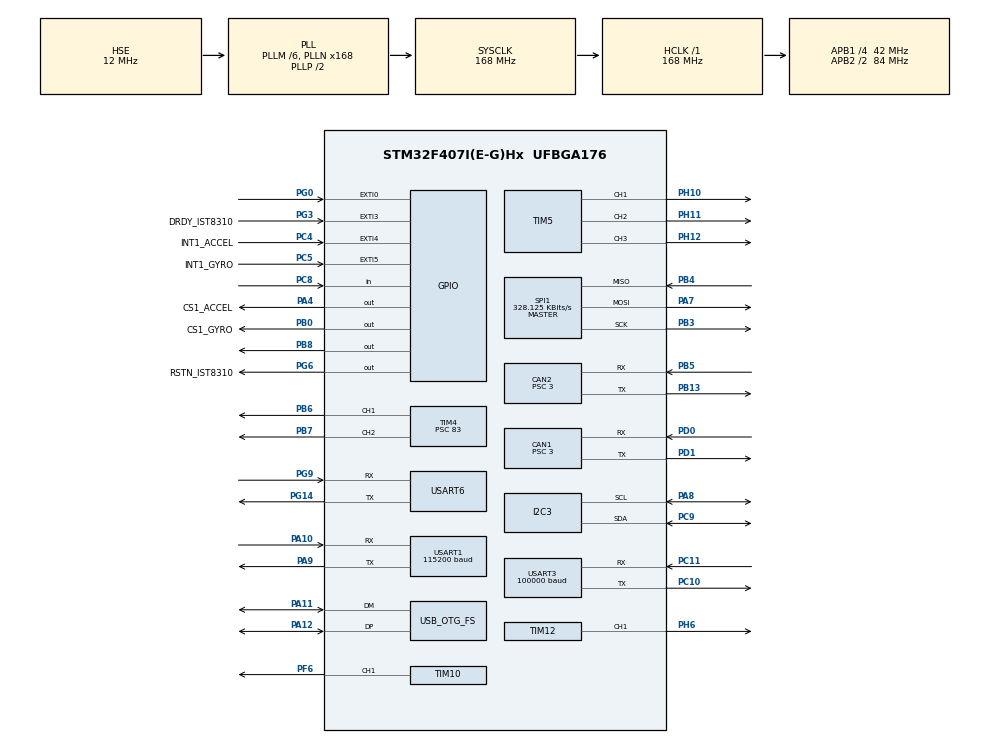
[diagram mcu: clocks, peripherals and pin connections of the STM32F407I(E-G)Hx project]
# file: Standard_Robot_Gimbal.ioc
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Dma.USART6_TX.3.MemInc=DMA_MINC_ENABLE
PH0-OSC_IN.Signal=RCC_OSC_IN
Dma.USART3_RX.1.Mode=DMA_NORMAL
Dma.USART6_TX.3.PeriphInc=DMA_PINC_DISABLE
PG6.PinState=GPIO_PIN_SET
PH12.Signal=S_TIM5_CH3
SPI1.VirtualType=VM_MASTER
PG6.GPIO_Label=RSTN_IST8310
PG0.Signal=GPXTI0
VP_RTC_VS_RTC_Activate.Mode=RTC_Enabled
Dma.SPI1_RX.4.PeriphInc=DMA_PINC_DISABLE
PB13.Signal=CAN2_TX
RCC.SYSCLKSource=RCC_SYSCLKSOURCE_PLLCLK
Dma.SPI1_TX.5.Instance=DMA2_Stream3
RTC.SynchPrediv=3199
USART3.BaudRate=100000
Dma.USART1_TX.0.Direction=DMA_MEMORY_TO_PERIPH
Dma.USART3_RX.1.Instance=DMA1_Stream1
NVIC.CAN1_TX_IRQn=true\:5\:0\:false\:false\:true\:true\:true\:true
SPI1.Direction=SPI_DIRECTION_2LINES
RCC.APB2TimFreq_Value=168000000
VP_TIM10_VS_ClockSourceINT.Mode=Enable_Timer
PB6.Signal=S_TIM4_CH1
SPI1.CalculateBaudRate=328.125 KBits/s
PD0.Signal=CAN1_RX
Dma.SPI1_RX.4.MemDataAlignment=DMA_MDATAALIGN_BYTE
PB3.Mode=Full_Duplex_Master
TIM10.Channel=TIM_CHANNEL_1
TIM12.Period=31111
PG14.Mode=Asynchronous
PG6.GPIO_PuPd=GPIO_PULLUP
SH.S_TIM12_CH1.0=TIM12_CH1,PWM Generation1 CH1
PC4.GPIO_Label=INT1_ACCEL
Dma.USART3_RX.1.Priority=DMA_PRIORITY_HIGH
PC9.Mode=I2C
SH.S_TIM4_CH2.0=TIM4_CH2,PWM Generation2 CH2
Dma.SPI1_TX.5.FIFOMode=DMA_FIFOMODE_DISABLE
PA8.Signal=I2C3_SCL
Dma.SPI1_TX.5.Priority=DMA_PRIORITY_HIGH
TIM4.Period=19999
Dma.USART1_TX.0.PeriphDataAlignment=DMA_PDATAALIGN_BYTE
PG0.GPIO_PuPd=GPIO_PULLUP
CAN1.Prescaler=3
Mcu.Package=UFBGA176
Dma.USART3_RX.1.FIFOMode=DMA_FIFOMODE_DISABLE
NVIC.TimeBase=TIM3_IRQn
Dma.USART3_RX.1.Direction=DMA_PERIPH_TO_MEMORY
NVIC.TimeBaseIP=TIM3
PA10.Signal=USART1_RX
PC11.Mode=Asynchronous
RCC.APB2CLKDivider=RCC_HCLK_DIV2
Dma.SPI1_TX.5.Direction=DMA_MEMORY_TO_PERIPH
NVIC.DMA2_Stream2_IRQn=true\:5\:0\:false\:false\:true\:true\:false\:true
SH.S_TIM4_CH1.0=TIM4_CH1,PWM Generation1 CH1
RCC.APB1TimFreq_Value=84000000
PB13.Mode=CAN_Activate
NVIC.USART1_IRQn=true\:5\:0\:false\:false\:true\:true\:true\:true
CAN1.CalculateTimeBit=999.99
PA4.GPIO_Label=CS1_ACCEL
PG6.GPIO_Speed=GPIO_SPEED_FREQ_MEDIUM
CAN1.CalculateTimeQuantum=71.42857142857143
CAN2.CalculateBaudRate=1000000
NVIC.EXTI4_IRQn=true\:5\:0\:false\:false\:true\:true\:true\:true
PC4.GPIO_ModeDefaultEXTI=GPIO_MODE_IT_FALLING
NVIC.CAN2_TX_IRQn=true\:5\:0\:false\:false\:true\:true\:true\:true
FREERTOS.Tasks01=Gimbal_Task,40,512,gimbal_task,As weak,NULL,Dynamic,NULL,NULL;INS_Task,24,512,INS_task,As weak,NULL,Dynamic,NULL,NULL;Detect_Task,24,256,detect_task,As weak,NULL,Dynamic,NULL,NULL
Dma.SPI1_TX.5.MemDataAlignment=DMA_MDATAALIGN_BYTE
PG9.Signal=USART6_RX
CAN1.CalculateBaudRate=1000000
PG9.Mode=Asynchronous
PD1.Signal=CAN1_TX
Dma.USART3_RX.1.MemDataAlignment=DMA_MDATAALIGN_BYTE
TIM5.Channel-PWM\ Generation3\ CH3=TIM_CHANNEL_3
SPI1.CLKPhase=SPI_PHASE_2EDGE
NVIC.DMA2_Stream1_IRQn=true\:5\:0\:false\:false\:true\:false\:false\:true
RCC.APB1CLKDivider=RCC_HCLK_DIV4
Dma.SPI1_RX.4.Instance=DMA2_Stream2
Dma.SPI1_RX.4.Mode=DMA_NORMAL
PA9.Signal=USART1_TX
Dma.SPI1_TX.5.Mode=DMA_NORMAL
NVIC.DMA2_Stream6_IRQn=true\:5\:0\:false\:false\:true\:true\:false\:true
PG0.GPIO_ModeDefaultEXTI=GPIO_MODE_IT_FALLING
PC5.GPIO_ModeDefaultEXTI=GPIO_MODE_IT_FALLING
TIM12.Prescaler=1281
Dma.USART6_TX.3.Direction=DMA_MEMORY_TO_PERIPH
PD1.Mode=CAN_Activate
NVIC.TIM3_IRQn=true\:0\:0\:false\:false\:true\:false\:false\:true
SPI1.Mode=SPI_MODE_MASTER
PA13.Mode=Serial_Wire
TIM5.Channel-PWM\ Generation2\ CH2=TIM_CHANNEL_2
PA4.Signal=GPIO_Output
PB5.Signal=CAN2_RX
Dma.SPI1_TX.5.PeriphInc=DMA_PINC_DISABLE
USART1.VirtualMode=VM_ASYNC
PA11.Signal=USB_OTG_FS_DM
TIM5.Channel-PWM\ Generation1\ CH1=TIM_CHANNEL_1
ProjectManager.HeapSize=0x2000
PH6.Signal=S_TIM12_CH1
VP_TIM4_VS_ClockSourceINT.Mode=Internal
NVIC.PriorityGroup=NVIC_PRIORITYGROUP_4
Dma.SPI1_TX.5.PeriphDataAlignment=DMA_PDATAALIGN_BYTE
PG3.GPIO_ModeDefaultEXTI=GPIO_MODE_IT_FALLING
PA8.Mode=I2C
PG3.GPIO_Label=DRDY_IST8310
Dma.USART6_RX.2.PeriphInc=DMA_PINC_DISABLE
PB0.Signal=GPIO_Output
NVIC.CAN1_RX0_IRQn=true\:5\:0\:false\:false\:true\:true\:true\:true
Dma.SPI1_RX.4.PeriphDataAlignment=DMA_PDATAALIGN_BYTE
Mcu.Family=STM32F4
NVIC.USART3_IRQn=true\:5\:0\:false\:false\:true\:true\:true\:true
USB_DEVICE.CLASS_NAME_FS=CDC
RCC.CortexFreq_Value=168000000
PG6.Signal=GPIO_Output
NVIC.CAN2_RX0_IRQn=true\:5\:0\:false\:false\:true\:true\:true\:true
PH10.Signal=S_TIM5_CH1
CAN2.CalculateTimeBit=999.99
USART1.BaudRate=115200
Dma.USART6_RX.2.Direction=DMA_PERIPH_TO_MEMORY
PC10.Signal=USART3_TX
SH.S_TIM5_CH2.0=TIM5_CH2,PWM Generation2 CH2
NVIC.EXTI3_IRQn=true\:5\:0\:false\:false\:true\:true\:true\:true
PA11.Mode=Device_Only
PB0.GPIO_Label=CS1_GYRO
USB_DEVICE.VirtualMode-CDC_FS=Cdc
Dma.USART6_RX.2.MemDataAlignment=DMA_MDATAALIGN_BYTE
ProjectManager.StackSize=0x2000
PG3.GPIO_PuPd=GPIO_PULLUP
VP_FREERTOS_VS_CMSIS_V2.Mode=CMSIS_V2
Dma.USART6_TX.3.PeriphDataAlignment=DMA_PDATAALIGN_BYTE
Dma.USART1_TX.0.Priority=DMA_PRIORITY_MEDIUM
PA12.Signal=USB_OTG_FS_DP
Dma.USART3_RX.1.MemInc=DMA_MINC_ENABLE
SPI1.CLKPolarity=SPI_POLARITY_HIGH
Dma.USART6_TX.3.Priority=DMA_PRIORITY_MEDIUM
PB0.PinState=GPIO_PIN_SET
RCC.HCLKFreq_Value=168000000
Dma.USART3_RX.1.PeriphDataAlignment=DMA_PDATAALIGN_BYTE
SH.S_TIM5_CH3.0=TIM5_CH3,PWM Generation3 CH3
Dma.USART6_RX.2.Instance=DMA2_Stream1
RCC.AHBFreq_Value=168000000
PH0-OSC_IN.Mode=HSE-External-Oscillator
RCC.HSE_VALUE=12000000
PA4.GPIO_PuPd=GPIO_PULLUP
PA4.GPIO_Speed=GPIO_SPEED_FREQ_HIGH
Dma.USART6_RX.2.Priority=DMA_PRIORITY_HIGH
PB4.Mode=Full_Duplex_Master
PA14.Mode=Serial_Wire
CAN2.Prescaler=3
PB5.Mode=CAN_Activate
RTC.AsynchPrediv=124
PB7.Signal=S_TIM4_CH2
VP_TIM12_VS_ClockSourceINT.Mode=Internal
Dma.SPI1_RX.4.FIFOMode=DMA_FIFOMODE_DISABLE
Dma.SPI1_RX.4.MemInc=DMA_MINC_ENABLE
PH1-OSC_OUT.Mode=HSE-External-Oscillator
NVIC.DMA2_Stream7_IRQn=true\:5\:0\:false\:false\:true\:true\:false\:true
CAN2.BS1=CAN_BS1_10TQ
CAN2.BS2=CAN_BS2_3TQ
USART6.VirtualMode=VM_ASYNC
SH.S_TIM10_CH1.0=TIM10_CH1,PWM Generation1 CH1
NVIC.OTG_FS_IRQn=true\:5\:0\:false\:false\:true\:true\:false\:true
USB_OTG_FS.VirtualMode=Device_Only
Dma.USART1_TX.0.Instance=DMA2_Stream7
Dma.USART1_TX.0.FIFOMode=DMA_FIFOMODE_DISABLE
PA4.GPIO_ModeDefaultOutputPP=GPIO_MODE_OUTPUT_PP
Dma.USART6_TX.3.MemDataAlignment=DMA_MDATAALIGN_BYTE
Dma.Request2=USART6_RX
Dma.Request1=USART3_RX
Dma.Request4=SPI1_RX
Dma.Request3=USART6_TX
SH.S_TIM5_CH1.0=TIM5_CH1,PWM Generation1 CH1
Dma.Request5=SPI1_TX
PC5.Signal=GPXTI5
Dma.Request0=USART1_TX
SPI1.BaudRatePrescaler=SPI_BAUDRATEPRESCALER_256
PB4.Signal=SPI1_MISO
Dma.SPI1_TX.5.MemInc=DMA_MINC_ENABLE
TIM4.Channel-PWM\ Generation1\ CH1=TIM_CHANNEL_1
TIM10.Prescaler=1
I2C3.I2C_Mode=I2C_Fast
Dma.USART1_TX.0.MemInc=DMA_MINC_ENABLE
PA7.Mode=Full_Duplex_Master
Dma.USART1_TX.0.PeriphInc=DMA_PINC_DISABLE
PA10.Mode=Asynchronous
PH11.Signal=S_TIM5_CH2
USB_DEVICE.VirtualModeFS=Cdc_FS
PG3.Signal=GPXTI3
PC4.GPIO_PuPd=GPIO_PULLUP
PC11.Signal=USART3_RX
PC8.Signal=GPIO_Input
PC10.Mode=Asynchronous
PC4.Signal=GPXTI4
NVIC.DMA1_Stream1_IRQn=true\:5\:0\:false\:false\:true\:true\:false\:true
PC5.GPIO_PuPd=GPIO_PULLUP
Dma.USART6_TX.3.Mode=DMA_NORMAL
NVIC.USART6_IRQn=true\:5\:0\:false\:false\:true\:true\:true\:true
PB0.GPIO_Speed=GPIO_SPEED_FREQ_HIGH
PA13.Signal=SYS_JTMS-SWDIO
PA9.Mode=Asynchronous
VP_SYS_VS_tim3.Mode=TIM3
PA4.PinState=GPIO_PIN_SET
CAN1.BS2=CAN_BS2_3TQ
PF6.Signal=S_TIM10_CH1
CAN1.BS1=CAN_BS1_10TQ
ProjectManager.TargetToolchain=STM32CubeIDE
Dma.USART6_RX.2.MemInc=DMA_MINC_ENABLE
VP_USB_DEVICE_VS_USB_DEVICE_CDC_FS.Mode=CDC_FS
Dma.USART6_RX.2.PeriphDataAlignment=DMA_PDATAALIGN_BYTE
NVIC.DMA2_Stream3_IRQn=true\:5\:0\:false\:false\:true\:true\:false\:true
TIM4.Prescaler=83
RCC.LSE_VALUE=32768
CAN1.ABOM=ENABLE
PG14.Signal=USART6_TX
Dma.USART1_TX.0.Mode=DMA_NORMAL
board=custom
RCC.VCOOutputFreq_Value=336000000
Dma.USART6_RX.2.FIFOMode=DMA_FIFOMODE_DISABLE
Dma.USART6_RX.2.Mode=DMA_NORMAL
TIM10.Period=4999
TIM12.Channel-PWM\ Generation1\ CH1=TIM_CHANNEL_1
TIM4.Channel-PWM\ Generation2\ CH2=TIM_CHANNEL_2
RCC.APB2Freq_Value=84000000
CAN2.CalculateTimeQuantum=71.42857142857143
PH1-OSC_OUT.Signal=RCC_OSC_OUT
Mcu.Name=STM32F407I(E-G)Hx
PD0.Mode=CAN_Activate
Dma.SPI1_RX.4.Priority=DMA_PRIORITY_VERY_HIGH
RCC.48MHZClocksFreq_Value=48000000
NVIC.EXTI0_IRQn=true\:5\:0\:false\:false\:true\:true\:true\:true
PB3.Signal=SPI1_SCK
RCC.SYSCLKFreq_VALUE=168000000
Dma.SPI1_RX.4.Direction=DMA_PERIPH_TO_MEMORY
PA12.Mode=Device_Only
PC5.GPIO_Label=INT1_GYRO
USART3.VirtualMode=VM_ASYNC
NVIC.EXTI9_5_IRQn=true\:5\:0\:false\:false\:true\:true\:true\:true
Dma.USART1_TX.0.MemDataAlignment=DMA_MDATAALIGN_BYTE
PA14.Signal=SYS_JTCK-SWCLK
Dma.USART6_TX.3.FIFOMode=DMA_FIFOMODE_DISABLE
Dma.USART6_TX.3.Instance=DMA2_Stream6
RCC.HSI_VALUE=16000000
RCC.PLLQ=7
RCC.PLLM=6
RCC.PLLN=168
PB8.Signal=GPIO_Output
PC9.Signal=I2C3_SDA
RCC.APB1Freq_Value=42000000
PB0.GPIO_PuPd=GPIO_PULLUP
Dma.USART3_RX.1.PeriphInc=DMA_PINC_DISABLE
PA7.Signal=SPI1_MOSI

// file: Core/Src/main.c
/* USER CODE BEGIN Header */
/**
  ******************************************************************************
  * @file           : main.c
  * @brief          : Main program body
  ******************************************************************************
  * @attention
  *
  * <h2><center>&copy; Copyright (c) 2021 STMicroelectronics.
  * All rights reserved.</center></h2>
  *
  * This software component is licensed by ST under Ultimate Liberty license
  * SLA0044, the "License"; You may not use this file except in compliance with
  * the License. You may obtain a copy of the License at:
  *                             www.st.com/SLA0044
  *
  ******************************************************************************
  */
/* USER CODE END Header */
#include "main.h"
#include "cmsis_os.h"
#include "can.h"
#include "dma.h"
#include "i2c.h"
#include "rtc.h"
#include "spi.h"
#include "tim.h"
#include "usart.h"
#include "usb_device.h"
#include "gpio.h"

/* USER CODE BEGIN Includes */
#include "bsp_can.h"
#include "detect_task.h"
#include "gimbal_task.h"
#include "INS_task.h"
/* USER CODE END Includes */

void SystemClock_Config(void);
void MX_FREERTOS_Init(void);

int main(void)
{

  /* MCU Configuration--------------------------------------------------------*/

  /* Reset of all peripherals, Initializes the Flash interface and the Systick. */
  HAL_Init();

  /* Configure the system clock */
  SystemClock_Config();

  /* Initialize all configured peripherals */
  MX_GPIO_Init();
  MX_DMA_Init();
  MX_CAN1_Init();
  MX_CAN2_Init();
  MX_RTC_Init();
  MX_TIM4_Init();
  MX_TIM5_Init();
  MX_TIM12_Init();
  MX_USART1_UART_Init();
  MX_USART3_UART_Init();
  MX_SPI1_Init();
  MX_USART6_UART_Init();
  MX_TIM10_Init();
  MX_I2C3_Init();
  /* USER CODE BEGIN 2 */
  can_filter_init();
  remote_control_init();
  delay_init();
  /* USER CODE END 2 */

  /* Init scheduler */
  osKernelInitialize();  /* Call init function for freertos objects (in freertos.c) */
  MX_FREERTOS_Init();
  /* Start scheduler */
  osKernelStart();

  /* We should never get here as control is now taken by the scheduler */
  /* Infinite loop */
  while (1)
  {

  }
}

void SystemClock_Config(void)
{
  RCC_OscInitTypeDef RCC_OscInitStruct = {0};
  RCC_ClkInitTypeDef RCC_ClkInitStruct = {0};
  RCC_PeriphCLKInitTypeDef PeriphClkInitStruct = {0};

  /** Configure the main internal regulator output voltage
  */
  __HAL_RCC_PWR_CLK_ENABLE();
  __HAL_PWR_VOLTAGESCALING_CONFIG(PWR_REGULATOR_VOLTAGE_SCALE1);
  /** Initializes the RCC Oscillators according to the specified parameters
  * in the RCC_OscInitTypeDef structure.
  */
  RCC_OscInitStruct.OscillatorType = RCC_OSCILLATORTYPE_LSI|RCC_OSCILLATORTYPE_HSE;
  RCC_OscInitStruct.HSEState = RCC_HSE_ON;
  RCC_OscInitStruct.LSIState = RCC_LSI_ON;
  RCC_OscInitStruct.PLL.PLLState = RCC_PLL_ON;
  RCC_OscInitStruct.PLL.PLLSource = RCC_PLLSOURCE_HSE;
  RCC_OscInitStruct.PLL.PLLM = 6;
  RCC_OscInitStruct.PLL.PLLN = 168;
  RCC_OscInitStruct.PLL.PLLP = RCC_PLLP_DIV2;
  RCC_OscInitStruct.PLL.PLLQ = 7;
  if (HAL_RCC_OscConfig(&RCC_OscInitStruct) != HAL_OK)
  {
    Error_Handler();
  }
  /** Initializes the CPU, AHB and APB buses clocks
  */
  RCC_ClkInitStruct.ClockType = RCC_CLOCKTYPE_HCLK|RCC_CLOCKTYPE_SYSCLK
                              |RCC_CLOCKTYPE_PCLK1|RCC_CLOCKTYPE_PCLK2;
  RCC_ClkInitStruct.SYSCLKSource = RCC_SYSCLKSOURCE_PLLCLK;
  RCC_ClkInitStruct.AHBCLKDivider = RCC_SYSCLK_DIV1;
  RCC_ClkInitStruct.APB1CLKDivider = RCC_HCLK_DIV4;
  RCC_ClkInitStruct.APB2CLKDivider = RCC_HCLK_DIV2;

  if (HAL_RCC_ClockConfig(&RCC_ClkInitStruct, FLASH_LATENCY_5) != HAL_OK)
  {
    Error_Handler();
  }
  PeriphClkInitStruct.PeriphClockSelection = RCC_PERIPHCLK_RTC;
  PeriphClkInitStruct.RTCClockSelection = RCC_RTCCLKSOURCE_LSI;
  if (HAL_RCCEx_PeriphCLKConfig(&PeriphClkInitStruct) != HAL_OK)
  {
    Error_Handler();
  }
}

 /**
  * @brief  Period elapsed callback in non blocking mode
  * @note   This function is called  when TIM3 interrupt took place, inside
  * HAL_TIM_IRQHandler(). It makes a direct call to HAL_IncTick() to increment
  * a global variable "uwTick" used as application time base.
  * @param  htim : TIM handle
  * @retval None
  */
void HAL_TIM_PeriodElapsedCallback(TIM_HandleTypeDef *htim)
{
  if (htim->Instance == TIM3) {
    HAL_IncTick();
  }
}

void Error_Handler(void)
{
  __disable_irq();
  while (1)
  {
  }
}

/************************ (C) COPYRIGHT STMicroelectronics *****END OF FILE****/

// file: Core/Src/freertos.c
/* USER CODE BEGIN Header */
/**
  ******************************************************************************
  * File Name          : freertos.c
  * Description        : Code for freertos applications
  ******************************************************************************
  * @attention
  *
  * <h2><center>&copy; Copyright (c) 2021 STMicroelectronics.
  * All rights reserved.</center></h2>
  *
  * This software component is licensed by ST under Ultimate Liberty license
  * SLA0044, the "License"; You may not use this file except in compliance with
  * the License. You may obtain a copy of the License at:
  *                             www.st.com/SLA0044
  *
  ******************************************************************************
  */
/* USER CODE END Header */

#include "FreeRTOS.h"
#include "task.h"
#include "main.h"
#include "cmsis_os.h"

/* Definitions for Gimbal_Task */
osThreadId_t Gimbal_TaskHandle;
const osThreadAttr_t Gimbal_Task_attributes = {
  .name = "Gimbal_Task",
  .stack_size = 512 * 4,
  .priority = (osPriority_t) osPriorityHigh,
};
/* Definitions for INS_Task */
osThreadId_t INS_TaskHandle;
const osThreadAttr_t INS_Task_attributes = {
  .name = "INS_Task",
  .stack_size = 512 * 4,
  .priority = (osPriority_t) osPriorityNormal,
};
/* Definitions for Detect_Task */
osThreadId_t Detect_TaskHandle;
const osThreadAttr_t Detect_Task_attributes = {
  .name = "Detect_Task",
  .stack_size = 256 * 4,
  .priority = (osPriority_t) osPriorityNormal,
};

void gimbal_task(void *argument);
void INS_task(void *argument);
void detect_task(void *argument);

extern void MX_USB_DEVICE_Init(void);
void MX_FREERTOS_Init(void); /* (MISRA C 2004 rule 8.1) */

void MX_FREERTOS_Init(void) {

  /* Create the thread(s) */
  /* creation of Gimbal_Task */
  Gimbal_TaskHandle = osThreadNew(gimbal_task, NULL, &Gimbal_Task_attributes);

  /* creation of INS_Task */
  INS_TaskHandle = osThreadNew(INS_task, NULL, &INS_Task_attributes);

  /* creation of Detect_Task */
  Detect_TaskHandle = osThreadNew(detect_task, NULL, &Detect_Task_attributes);

}

__weak void gimbal_task(void *argument)
{
  /* init code for USB_DEVICE */
  MX_USB_DEVICE_Init();
  for(;;)
  {
    osDelay(1);
  }
}

__weak void INS_task(void *argument)
{
  for(;;)
  {
    osDelay(1);
  }
}

__weak void detect_task(void *argument)
{
  for(;;)
  {
    osDelay(1);
  }
}

/************************ (C) COPYRIGHT STMicroelectronics *****END OF FILE****/
